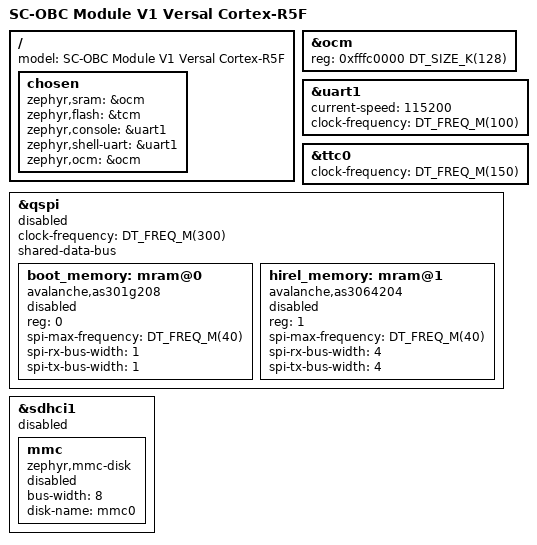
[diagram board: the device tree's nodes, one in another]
/*
 * Copyright (c) 2025 Space Cubics Inc.
 *
 * SPDX-License-Identifier: Apache-2.0
 */

/dts-v1/;
#include <arm/xilinx/versal_rpu.dtsi>
#include <freq.h>

/ {
	model = "SC-OBC Module V1 Versal Cortex-R5F";

	chosen {
		zephyr,sram = &ocm;
		zephyr,flash = &tcm;
		zephyr,console = &uart1;
		zephyr,shell-uart = &uart1;
		zephyr,ocm = &ocm;
	};
};

&ocm {
	/*
	 * Versal OCM is 256 KiB at 0xfffc0000.
	 *
	 *   0xfffc0000 - 0xfffdffff: lower 128 KiB, exposed to Zephyr
	 *   0xfffe0000 - 0xffffffff: upper 128 KiB, default TF-A BL31 location
	 *
	 * Keep the upper half out of the Zephyr memory region to avoid
	 * overwriting the TF-A BL31 location.
	 */
	reg = <0xfffc0000 DT_SIZE_K(128)>;
	status = "okay";
};

&uart1 {
	current-speed = <115200>;
	clock-frequency = <DT_FREQ_M(100)>;
	status = "okay";
};

&ttc0 {
	clock-frequency = <DT_FREQ_M(150)>;
	status = "okay";
};

&qspi {
	clock-frequency = <DT_FREQ_M(300)>;
	shared-data-bus;
	status = "disabled";

	boot_memory: mram@0 {
		compatible = "avalanche,as301g208";
		reg = <0>;
		spi-max-frequency = <DT_FREQ_M(40)>;
		/*
		 * The Safety Processor switches two independent boot memory banks
		 * onto CS0. Use SPI to avoid bank-specific QPI state. The driver
		 * requires matching TX/RX widths; mixed-width transfers are not
		 * supported. QPI (4-4-4) is also supported by setting both widths
		 * to 4, provided both banks are initialized before switching.
		 */
		spi-rx-bus-width = <1>;
		spi-tx-bus-width = <1>;
		status = "disabled";
	};

	hirel_memory: mram@1 {
		compatible = "avalanche,as3064204";
		reg = <1>;
		spi-max-frequency = <DT_FREQ_M(40)>;
		spi-rx-bus-width = <4>;
		spi-tx-bus-width = <4>;
		status = "disabled";
	};
};

&sdhci1 {
	status = "disabled";

	mmc {
		compatible = "zephyr,mmc-disk";
		bus-width = <8>;
		disk-name = "mmc0";
		status = "disabled";
	};
};
